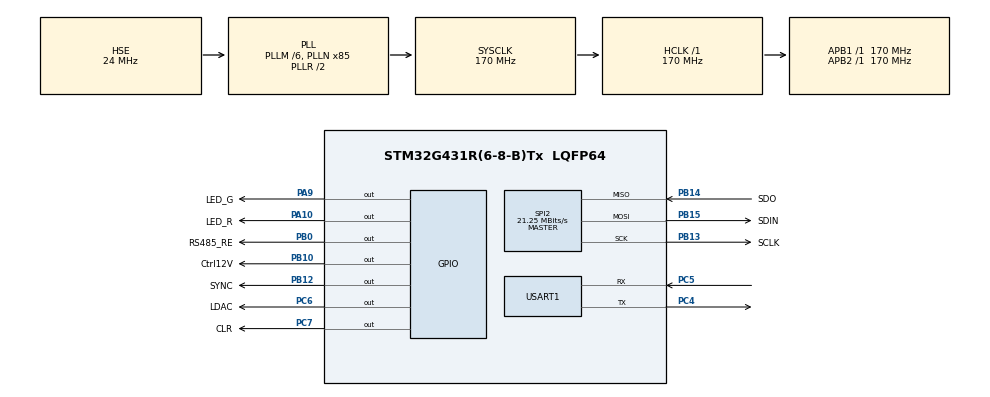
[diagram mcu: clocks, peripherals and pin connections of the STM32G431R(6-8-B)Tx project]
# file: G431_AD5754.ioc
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Dma.Request0=USART1_RX
Dma.USART1_RX.0.Direction=DMA_PERIPH_TO_MEMORY
Dma.USART1_RX.0.EventEnable=DISABLE
Dma.USART1_RX.0.Instance=DMA1_Channel1
Dma.USART1_RX.0.MemDataAlignment=DMA_MDATAALIGN_BYTE
Dma.USART1_RX.0.MemInc=DMA_MINC_ENABLE
Dma.USART1_RX.0.Mode=DMA_NORMAL
Dma.USART1_RX.0.PeriphDataAlignment=DMA_PDATAALIGN_BYTE
Dma.USART1_RX.0.PeriphInc=DMA_PINC_DISABLE
Dma.USART1_RX.0.Polarity=HAL_DMAMUX_REQ_GEN_RISING
Dma.USART1_RX.0.Priority=DMA_PRIORITY_LOW
Dma.USART1_RX.0.RequestNumber=1
Dma.USART1_RX.0.SignalID=NONE
Dma.USART1_RX.0.SyncEnable=DISABLE
Dma.USART1_RX.0.SyncPolarity=HAL_DMAMUX_SYNC_NO_EVENT
Dma.USART1_RX.0.SyncRequestNumber=1
Dma.USART1_RX.0.SyncSignalID=NONE
FREERTOS.Tasks01=defaultTask,0,128,StartDefaultTask,Default,NULL,Dynamic,NULL,NULL;myTask02,0,128,StartTask02,Default,NULL,Dynamic,NULL,NULL;myTask03,0,128,StartTask03,Default,NULL,Dynamic,NULL,NULL
Mcu.Family=STM32G4
Mcu.Name=STM32G431R(6-8-B)Tx
Mcu.Package=LQFP64
NVIC.DMA1_Channel1_IRQn=true\:5\:0\:false\:false\:true\:true\:false\:true\:true
NVIC.PriorityGroup=NVIC_PRIORITYGROUP_4
NVIC.TIM6_DAC_IRQn=true\:15\:0\:false\:false\:true\:false\:false\:true\:true
NVIC.TimeBase=TIM6_DAC_IRQn
NVIC.TimeBaseIP=TIM6
NVIC.USART1_IRQn=true\:5\:0\:false\:false\:true\:true\:true\:true\:true
PA10.GPIO_Label=LED_R
PA10.Signal=GPIO_Output
PA13.Mode=Serial_Wire
PA13.Signal=SYS_JTMS-SWDIO
PA14.Mode=Serial_Wire
PA14.Signal=SYS_JTCK-SWCLK
PA9.GPIO_Label=LED_G
PA9.Signal=GPIO_Output
PB0.GPIO_Label=RS485_RE
PB0.GPIO_PuPd=GPIO_PULLUP
PB0.GPIO_Speed=GPIO_SPEED_FREQ_VERY_HIGH
PB0.PinState=GPIO_PIN_RESET
PB0.Signal=GPIO_Output
PB10.GPIO_Label=Ctrl12V
PB10.Signal=GPIO_Output
PB12.GPIO_Label=SYNC
PB12.GPIO_PuPd=GPIO_PULLUP
PB12.GPIO_Speed=GPIO_SPEED_FREQ_HIGH
PB12.PinState=GPIO_PIN_SET
PB12.Signal=GPIO_Output
PB13.GPIO_Label=SCLK
PB13.GPIO_PuPd=GPIO_PULLUP
PB13.Mode=Full_Duplex_Master
PB13.Signal=SPI2_SCK
PB14.GPIO_Label=SDO
PB14.Mode=Full_Duplex_Master
PB14.Signal=SPI2_MISO
PB15.GPIO_Label=SDIN
PB15.Mode=Full_Duplex_Master
PB15.Signal=SPI2_MOSI
PC4.Mode=Asynchronous
PC4.Signal=USART1_TX
PC5.Mode=Asynchronous
PC5.Signal=USART1_RX
PC6.GPIO_Label=LDAC
PC6.Signal=GPIO_Output
PC7.GPIO_Label=CLR
PC7.GPIO_Speed=GPIO_SPEED_FREQ_HIGH
PC7.PinState=GPIO_PIN_SET
PC7.Signal=GPIO_Output
PF0-OSC_IN.Mode=HSE-External-Oscillator
PF0-OSC_IN.Signal=RCC_OSC_IN
PF1-OSC_OUT.Mode=HSE-External-Oscillator
PF1-OSC_OUT.Signal=RCC_OSC_OUT
ProjectManager.HeapSize=0x800
ProjectManager.StackSize=0x800
ProjectManager.TargetToolchain=MDK-ARM V5
RCC.ADC12Freq_Value=170000000
RCC.AHBFreq_Value=170000000
RCC.APB1Freq_Value=170000000
RCC.APB1TimFreq_Value=170000000
RCC.APB2Freq_Value=170000000
RCC.APB2TimFreq_Value=170000000
RCC.CortexFreq_Value=170000000
RCC.EXTERNAL_CLOCK_VALUE=12288000
RCC.HCLKFreq_Value=170000000
RCC.HSE_VALUE=24000000
RCC.HSI48_VALUE=48000000
RCC.HSI_VALUE=16000000
RCC.LSE_VALUE=32768
RCC.PLLM=RCC_PLLM_DIV6
RCC.PLLN=85
RCC.PLLSourceVirtual=RCC_PLLSOURCE_HSE
RCC.SYSCLKFreq_VALUE=170000000
RCC.SYSCLKSource=RCC_SYSCLKSOURCE_PLLCLK
RCC.USBFreq_Value=170000000
RCC.VCOOutputFreq_Value=340000000
SPI2.BaudRatePrescaler=SPI_BAUDRATEPRESCALER_8
SPI2.CLKPhase=SPI_PHASE_2EDGE
SPI2.CalculateBaudRate=21.25 MBits/s
SPI2.DataSize=SPI_DATASIZE_8BIT
SPI2.Direction=SPI_DIRECTION_2LINES
SPI2.Mode=SPI_MODE_MASTER
SPI2.VirtualType=VM_MASTER
TIM3.Prescaler=170-1
TIM4.Prescaler=170-1
USART1.VirtualMode-Asynchronous=VM_ASYNC
VP_FREERTOS_VS_CMSIS_V1.Mode=CMSIS_V1
VP_SYS_VS_DBSignals.Mode=DisableDeadBatterySignals
VP_SYS_VS_tim6.Mode=TIM6
VP_TIM3_VS_ClockSourceINT.Mode=Internal
VP_TIM4_VS_ClockSourceINT.Mode=Internal
board=custom

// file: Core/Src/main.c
/* USER CODE BEGIN Header */
/**
  ******************************************************************************
  * @file           : main.c
  * @brief          : Main program body
  ******************************************************************************
  * @attention
  *
  * Copyright (c) 2024 STMicroelectronics.
  * All rights reserved.
  *
  * This software is licensed under terms that can be found in the LICENSE file
  * in the root directory of this software component.
  * If no LICENSE file comes with this software, it is provided AS-IS.
  *
  ******************************************************************************
  */
/* USER CODE END Header */
#include "main.h"
#include "cmsis_os.h"
#include "dma.h"
#include "spi.h"
#include "tim.h"
#include "usart.h"
#include "gpio.h"

/* USER CODE BEGIN Includes */
#include "ad5754r.h"
/* USER CODE END Includes */

void SystemClock_Config(void);
void MX_FREERTOS_Init(void);

int main(void)
{

  /* MCU Configuration--------------------------------------------------------*/

  /* Reset of all peripherals, Initializes the Flash interface and the Systick. */
  HAL_Init();

  /* Configure the system clock */
  SystemClock_Config();

  /* Initialize all configured peripherals */
  MX_GPIO_Init();
  MX_DMA_Init();
  MX_USART1_UART_Init();
  MX_TIM4_Init();
  MX_TIM3_Init();
  MX_SPI2_Init();
  /* USER CODE BEGIN 2 */
	AD5754_Init();
	ConfigAD5754R();
  /* USER CODE END 2 */

  /* Call init function for freertos objects (in cmsis_os2.c) */
  MX_FREERTOS_Init();

  /* Start scheduler */
  osKernelStart();

  /* We should never get here as control is now taken by the scheduler */

  /* Infinite loop */
  while (1)
  {

  }
}

void SystemClock_Config(void)
{
  RCC_OscInitTypeDef RCC_OscInitStruct = {0};
  RCC_ClkInitTypeDef RCC_ClkInitStruct = {0};

  /** Configure the main internal regulator output voltage
  */
  HAL_PWREx_ControlVoltageScaling(PWR_REGULATOR_VOLTAGE_SCALE1_BOOST);

  /** Initializes the RCC Oscillators according to the specified parameters
  * in the RCC_OscInitTypeDef structure.
  */
  RCC_OscInitStruct.OscillatorType = RCC_OSCILLATORTYPE_HSE;
  RCC_OscInitStruct.HSEState = RCC_HSE_ON;
  RCC_OscInitStruct.PLL.PLLState = RCC_PLL_ON;
  RCC_OscInitStruct.PLL.PLLSource = RCC_PLLSOURCE_HSE;
  RCC_OscInitStruct.PLL.PLLM = RCC_PLLM_DIV6;
  RCC_OscInitStruct.PLL.PLLN = 85;
  RCC_OscInitStruct.PLL.PLLP = RCC_PLLP_DIV2;
  RCC_OscInitStruct.PLL.PLLQ = RCC_PLLQ_DIV2;
  RCC_OscInitStruct.PLL.PLLR = RCC_PLLR_DIV2;
  if (HAL_RCC_OscConfig(&RCC_OscInitStruct) != HAL_OK)
  {
    Error_Handler();
  }

  /** Initializes the CPU, AHB and APB buses clocks
  */
  RCC_ClkInitStruct.ClockType = RCC_CLOCKTYPE_HCLK|RCC_CLOCKTYPE_SYSCLK
                              |RCC_CLOCKTYPE_PCLK1|RCC_CLOCKTYPE_PCLK2;
  RCC_ClkInitStruct.SYSCLKSource = RCC_SYSCLKSOURCE_PLLCLK;
  RCC_ClkInitStruct.AHBCLKDivider = RCC_SYSCLK_DIV1;
  RCC_ClkInitStruct.APB1CLKDivider = RCC_HCLK_DIV1;
  RCC_ClkInitStruct.APB2CLKDivider = RCC_HCLK_DIV1;

  if (HAL_RCC_ClockConfig(&RCC_ClkInitStruct, FLASH_LATENCY_4) != HAL_OK)
  {
    Error_Handler();
  }
}

void HAL_TIM_PeriodElapsedCallback(TIM_HandleTypeDef *htim)
{
  if (htim->Instance == TIM6) {
    HAL_IncTick();
  }
}

void Error_Handler(void)
{
  __disable_irq();
  while (1)
  {
  }
}

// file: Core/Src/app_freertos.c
/* USER CODE BEGIN Header */
/**
  ******************************************************************************
  * File Name          : app_freertos.c
  * Description        : Code for freertos applications
  ******************************************************************************
  * @attention
  *
  * Copyright (c) 2024 STMicroelectronics.
  * All rights reserved.
  *
  * This software is licensed under terms that can be found in the LICENSE file
  * in the root directory of this software component.
  * If no LICENSE file comes with this software, it is provided AS-IS.
  *
  ******************************************************************************
  */
/* USER CODE END Header */

#include "FreeRTOS.h"
#include "task.h"
#include "main.h"
#include "cmsis_os.h"

/* USER CODE BEGIN Includes */
#include "appmain.h"
/* USER CODE END Includes */

osThreadId defaultTaskHandle;
osThreadId myTask02Handle;
osThreadId myTask03Handle;

void StartDefaultTask(void const * argument);
void StartTask02(void const * argument);
void StartTask03(void const * argument);

void MX_FREERTOS_Init(void); /* (MISRA C 2004 rule 8.1) */

void MX_FREERTOS_Init(void) {

  /* Create the thread(s) */
  /* definition and creation of defaultTask */
  osThreadDef(defaultTask, StartDefaultTask, osPriorityNormal, 0, 128);
  defaultTaskHandle = osThreadCreate(osThread(defaultTask), NULL);

  /* definition and creation of myTask02 */
  osThreadDef(myTask02, StartTask02, osPriorityNormal, 0, 128);
  myTask02Handle = osThreadCreate(osThread(myTask02), NULL);

  /* definition and creation of myTask03 */
  osThreadDef(myTask03, StartTask03, osPriorityNormal, 0, 128);
  myTask03Handle = osThreadCreate(osThread(myTask03), NULL);

}

void StartDefaultTask(void const * argument)
{
  /* USER CODE BEGIN StartDefaultTask */
  /* Infinite loop */
  for(;;)
  {
		HAL_GPIO_TogglePin(LED_G_GPIO_Port,LED_G_Pin);
    osDelay(500);
  }
  /* USER CODE END StartDefaultTask */
}

void StartTask02(void const * argument)
{
  /* USER CODE BEGIN StartTask02 */
  /* Infinite loop */
  for(;;)
  {
    osDelay(1000);
		HAL_GPIO_WritePin(Ctrl12V_GPIO_Port, Ctrl12V_Pin, GPIO_PIN_SET);
  }
  /* USER CODE END StartTask02 */
}

void StartTask03(void const * argument)
{
  /* USER CODE BEGIN StartTask03 */
  /* Infinite loop */
  for(;;)
  {
//		edfa_init();
    osDelay(500);
  }
  /* USER CODE END StartTask03 */
}
